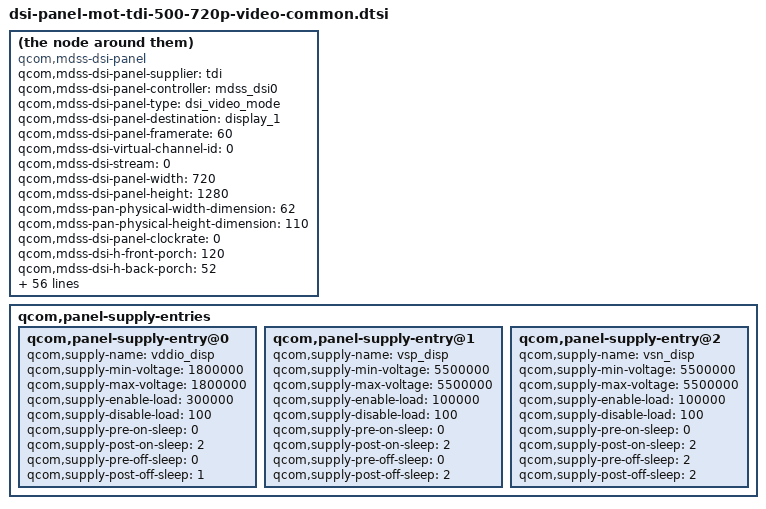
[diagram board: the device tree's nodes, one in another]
/* Copyright (c) 2015, Motorola Mobility LLC. All rights reserved.
 *
 * This program is free software; you can redistribute it and/or modify
 * it under the terms of the GNU General Public License version 2 and
 * only version 2 as published by the Free Software Foundation.
 *
 * This program is distributed in the hope that it will be useful,
 * but WITHOUT ANY WARRANTY; without even the implied warranty of
 * MERCHANTABILITY or FITNESS FOR A PARTICULAR PURPOSE.  See the
 * GNU General Public License for more details.
 */

compatible = "qcom,mdss-dsi-panel";
qcom,mdss-dsi-panel-supplier = "tdi";
qcom,mdss-dsi-panel-controller = <&mdss_dsi0>;
qcom,mdss-dsi-panel-type = "dsi_video_mode";
qcom,mdss-dsi-panel-destination = "display_1";
qcom,mdss-dsi-panel-framerate = <60>;
qcom,mdss-dsi-virtual-channel-id = <0>;
qcom,mdss-dsi-stream = <0>;
qcom,mdss-dsi-panel-width = <720>;
qcom,mdss-dsi-panel-height = <1280>;
qcom,mdss-pan-physical-width-dimension = <62>;
qcom,mdss-pan-physical-height-dimension = <110>;

qcom,mdss-dsi-panel-clockrate = <0>;
qcom,mdss-dsi-h-front-porch = <120>;
qcom,mdss-dsi-h-back-porch = <52>;
qcom,mdss-dsi-h-pulse-width = <8>;
qcom,mdss-dsi-h-sync-skew = <0>;
qcom,mdss-dsi-v-back-porch = <10>;
qcom,mdss-dsi-v-front-porch = <11>;
qcom,mdss-dsi-v-pulse-width = <1>;
qcom,mdss-dsi-h-left-border = <0>;
qcom,mdss-dsi-h-right-border = <0>;
qcom,mdss-dsi-v-top-border = <0>;
qcom,mdss-dsi-v-bottom-border = <0>;
qcom,mdss-dsi-bpp = <24>;
qcom,mdss-dsi-underflow-color = <0xff>;
qcom,mdss-dsi-border-color = <0>;

qcom,mdss-dsi-reset-sequence = <0 6>, <1 11>, <0 2>, <1 11>;
qcom,mdss-dsi-dis-reset-sequence = <1 101>, <0 0>;

qcom,mdss-dsi-pre-on-command = [
	15 01 00 00 00 00 02 53 2C		/* CTRL Display */
	15 01 00 00 00 00 02 51 FF		/* Brightness */
	15 01 00 00 00 00 02 55 01		/* UI CABC mode */
	15 01 00 00 00 00 02 36 C0];	/* Rotate display 180 degree */

qcom,mdss-dsi-on-command = [
	05 01 00 00 78 00 01 11			/* Exit sleep */
	05 01 00 00 00 00 01 29];		/* Display on */

qcom,mdss-dsi-off-command = [
	05 01 00 00 11 00 01 28
	05 01 00 00 00 00 01 10];

qcom,mdss-dsi-on-command-state = "dsi_hs_mode";
qcom,mdss-dsi-off-command-state = "dsi_lp_mode";

qcom,mdss-dsi-cabc-ui-command = [15 01 00 00 00 00 02 55 01];
qcom,mdss-dsi-cabc-mv-command = [15 01 00 00 00 00 02 55 03];

qcom,mdss-dsi-h-sync-pulse = <1>;
qcom,mdss-dsi-traffic-mode = "burst_mode";
qcom,mdss-dsi-bllp-eof-power-mode;
qcom,mdss-dsi-bllp-power-mode;
qcom,mdss-dsi-lp11-init;
qcom,mdss-dsi-tx-eot-append;
qcom,mdss-dsi-dma-trigger = "trigger_sw";
qcom,mdss-dsi-mdp-trigger = "none";
qcom,mdss-dsi-lane-0-state;
qcom,mdss-dsi-lane-1-state;
qcom,mdss-dsi-lane-2-state;
qcom,mdss-dsi-lane-3-state;

qcom,mdss-dsi-panel-timings = [7B 1A 10 00 3E 42 16 1E 15 03 04 00];
qcom,mdss-dsi-t-clk-post = <0x04>;
qcom,mdss-dsi-t-clk-pre = <0x1A>;

qcom,mdss-dsi-bl-min-level = <1>;
qcom,mdss-dsi-bl-max-level = <255>;
qcom,mdss-dsi-bl-pmic-control-type = "bl_ctrl_wled";

qcom,cont-splash-enabled;
qcom,esd-check-enabled;
qcom,mdss-dsi-panel-status-check-mode = "reg_read";
qcom,mdss-dsi-panel-status-command = [06 01 00 01 00 00 01 0A];
qcom,mdss-dsi-panel-status-command-state = "dsi_hs_mode";
qcom,mdss-dsi-panel-status-value = <0x1C>;

qcom,panel-supply-entries {
	#address-cells = <1>;
	#size-cells = <0>;
	qcom,panel-supply-entry@0 {
		qcom,supply-name = "vddio_disp";
		qcom,supply-min-voltage = <1800000>;
		qcom,supply-max-voltage = <1800000>;
		qcom,supply-enable-load = <300000>;
		qcom,supply-disable-load = <100>;
		qcom,supply-pre-on-sleep = <0>;
		qcom,supply-post-on-sleep = <2>;
		qcom,supply-pre-off-sleep = <0>;
		qcom,supply-post-off-sleep = <1>;
	};
	qcom,panel-supply-entry@1 {
		qcom,supply-name = "vsp_disp";
		qcom,supply-min-voltage = <5500000>;
		qcom,supply-max-voltage = <5500000>;
		qcom,supply-enable-load = <100000>;
		qcom,supply-disable-load = <100>;
		qcom,supply-pre-on-sleep = <0>;
		qcom,supply-post-on-sleep = <2>;
		qcom,supply-pre-off-sleep = <0>;
		qcom,supply-post-off-sleep = <2>;
	};
	qcom,panel-supply-entry@2 {
		qcom,supply-name = "vsn_disp";
		qcom,supply-min-voltage = <5500000>;
		qcom,supply-max-voltage = <5500000>;
		qcom,supply-enable-load = <100000>;
		qcom,supply-disable-load = <100>;
		qcom,supply-pre-on-sleep = <0>;
		qcom,supply-post-on-sleep = <2>;
		qcom,supply-pre-off-sleep = <2>;
		qcom,supply-post-off-sleep = <2>;
	};
};
